# ESP32-P4-LP register map
Vendor: ESPRESSIF SYSTEMS (SHANGHAI) CO., LTD.; Series: ESP32 P-Series; File version: 3
CPU: RV32IMAC r0p0, little endian, no MPU, no FPU, 0 interrupt priority bits
Address unit: 32 bits
Registers are 32-bit, read-write, reset 0x0 unless marked. A register's access mark holds for its fields unless they carry their own. Offsets are from the block's base; [hi:lo] are bit positions; {n}, {i} and the like mark numbered series.

## LP_GPIO — Low-power General Purpose Input/Output
Base 0x5012A000
0x00 CLK_EN reset 0x1 — Reserved
  [0] REG_CLK_EN
0x04 VER_DATE reset 0x230323 — Reserved
  [27:0] REG_VER_DATE
0x08 OUT — Reserved
  [15:0] REG_GPIO_OUT_DATA
0x0C OUT_W1TS wo — Reserved
  [15:0] REG_GPIO_OUT_DATA_W1TS
0x10 OUT_W1TC wo — Reserved
  [15:0] REG_GPIO_OUT_DATA_W1TC
0x14 ENABLE — Reserved
  [15:0] REG_GPIO_ENABLE_DATA
0x18 ENABLE_W1TS wo — Reserved
  [15:0] REG_GPIO_ENABLE_DATA_W1TS
0x1C ENABLE_W1TC wo — Reserved
  [15:0] REG_GPIO_ENABLE_DATA_W1TC
0x20 STATUS — Reserved
  [15:0] REG_GPIO_STATUS_DATA
0x24 STATUS_W1TS wo — Reserved
  [15:0] REG_GPIO_STATUS_DATA_W1TS
0x28 STATUS_W1TC wo — Reserved
  [15:0] REG_GPIO_STATUS_DATA_W1TC
0x2C STATUS_NEXT ro — Reserved
  [15:0] REG_GPIO_STATUS_INTERRUPT_NEXT
0x30 IN ro — Reserved
  [15:0] REG_GPIO_IN_DATA_NEXT
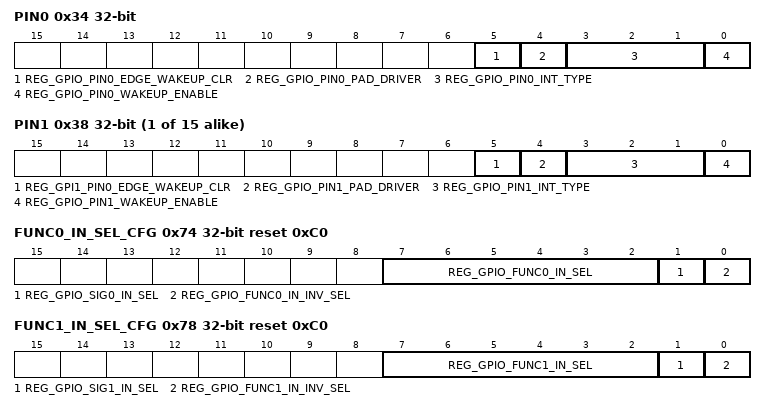
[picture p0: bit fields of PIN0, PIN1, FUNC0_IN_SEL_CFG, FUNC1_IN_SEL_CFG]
0x34 PIN0 access per field — Reserved
  [5] REG_GPIO_PIN0_EDGE_WAKEUP_CLR wo — need des
  [4] REG_GPIO_PIN0_PAD_DRIVER rw — Reserved
  [3:1] REG_GPIO_PIN0_INT_TYPE rw — Reserved
  [0] REG_GPIO_PIN0_WAKEUP_ENABLE rw — Reserved
{0x34+4i} PIN{i} access per field (i=1..15) — Reserved
  [5] REG_GPI{i}_PIN0_EDGE_WAKEUP_CLR wo — need des
  [4] REG_GPIO_PIN{i}_PAD_DRIVER rw — Reserved
  [3:1] REG_GPIO_PIN{i}_INT_TYPE rw — Reserved
  [0] REG_GPIO_PIN{i}_WAKEUP_ENABLE rw — Reserved
0x74 FUNC0_IN_SEL_CFG reset 0xC0 — Reserved
  [7:2] REG_GPIO_FUNC0_IN_SEL — reg_gpio_func0_in_sel[5:4]==2'b11->constant 1,reg_gpio_func0_in_sel[5:4]==2'b10->constant 0
  [1] REG_GPIO_SIG0_IN_SEL — Reserved
  [0] REG_GPIO_FUNC0_IN_INV_SEL — Reserved
0x78 FUNC1_IN_SEL_CFG reset 0xC0 — Reserved
  [7:2] REG_GPIO_FUNC1_IN_SEL — Reserved
  [1] REG_GPIO_SIG1_IN_SEL — Reserved
  [0] REG_GPIO_FUNC1_IN_INV_SEL — Reserved
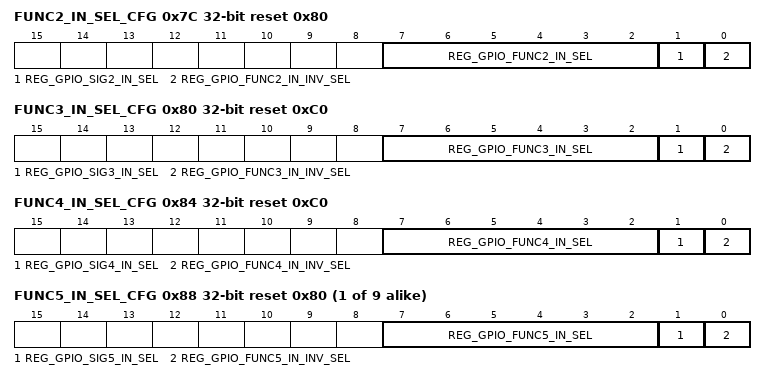
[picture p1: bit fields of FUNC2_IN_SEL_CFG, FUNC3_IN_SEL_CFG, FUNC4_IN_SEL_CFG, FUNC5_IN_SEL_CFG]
0x7C FUNC2_IN_SEL_CFG reset 0x80 — Reserved
  [7:2] REG_GPIO_FUNC2_IN_SEL — Reserved
  [1] REG_GPIO_SIG2_IN_SEL — Reserved
  [0] REG_GPIO_FUNC2_IN_INV_SEL — Reserved
0x80 FUNC3_IN_SEL_CFG reset 0xC0 — Reserved
  [7:2] REG_GPIO_FUNC3_IN_SEL — Reserved
  [1] REG_GPIO_SIG3_IN_SEL — Reserved
  [0] REG_GPIO_FUNC3_IN_INV_SEL — Reserved
0x84 FUNC4_IN_SEL_CFG reset 0xC0 — Reserved
  [7:2] REG_GPIO_FUNC4_IN_SEL — Reserved
  [1] REG_GPIO_SIG4_IN_SEL — Reserved
  [0] REG_GPIO_FUNC4_IN_INV_SEL — Reserved
{0x74+4i} FUNC{i}_IN_SEL_CFG reset 0x80 (i=5..13) — Reserved
  [7:2] REG_GPIO_FUNC{i}_IN_SEL — Reserved
  [1] REG_GPIO_SIG{i}_IN_SEL — Reserved
  [0] REG_GPIO_FUNC{i}_IN_INV_SEL — Reserved
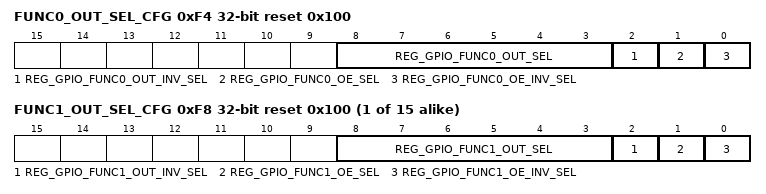
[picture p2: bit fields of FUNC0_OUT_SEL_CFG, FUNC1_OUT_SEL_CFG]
0xF4 FUNC0_OUT_SEL_CFG reset 0x100 — Reserved
  [8:3] REG_GPIO_FUNC0_OUT_SEL — reg_gpio_func0_out_sel[5:1]==16 -> output gpio register value to pad
  [2] REG_GPIO_FUNC0_OUT_INV_SEL — Reserved
  [1] REG_GPIO_FUNC0_OE_SEL — Reserved
  [0] REG_GPIO_FUNC0_OE_INV_SEL — Reserved
{0xF4+4i} FUNC{i}_OUT_SEL_CFG reset 0x100 (i=1..15) — Reserved
  [8:3] REG_GPIO_FUNC{i}_OUT_SEL — Reserved
  [2] REG_GPIO_FUNC{i}_OUT_INV_SEL — Reserved
  [1] REG_GPIO_FUNC{i}_OE_SEL — Reserved
  [0] REG_GPIO_FUNC{i}_OE_INV_SEL — Reserved

## LP_HUK — LP_HUK Peripheral
Base 0x50114000
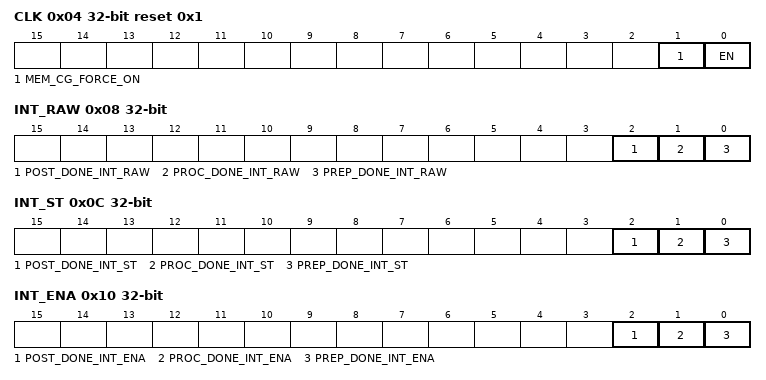
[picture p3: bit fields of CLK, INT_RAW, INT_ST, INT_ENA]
0x04 CLK reset 0x1 — HUK Generator clock gate control register
  [1] MEM_CG_FORCE_ON — Write 1 to force on memory clock gate.
  [0] EN — Write 1 to force on register clock gate.
0x08 INT_RAW ro — HUK Generator interrupt raw register, valid in level.
  [2] POST_DONE_INT_RAW — The raw interrupt status bit for the huk_post_done_int interrupt
  [1] PROC_DONE_INT_RAW — The raw interrupt status bit for the huk_proc_done_int interrupt
  [0] PREP_DONE_INT_RAW — The raw interrupt status bit for the huk_prep_done_int interrupt
0x0C INT_ST ro — HUK Generator interrupt status register.
  [2] POST_DONE_INT_ST — The masked interrupt status bit for the huk_post_done_int interrupt
  [1] PROC_DONE_INT_ST — The masked interrupt status bit for the huk_proc_done_int interrupt
  [0] PREP_DONE_INT_ST — The masked interrupt status bit for the huk_prep_done_int interrupt
0x10 INT_ENA — HUK Generator interrupt enable register.
  [2] POST_DONE_INT_ENA — The interrupt enable bit for the huk_post_done_int interrupt
  [1] PROC_DONE_INT_ENA — The interrupt enable bit for the huk_proc_done_int interrupt
  [0] PREP_DONE_INT_ENA — The interrupt enable bit for the huk_prep_done_int interrupt
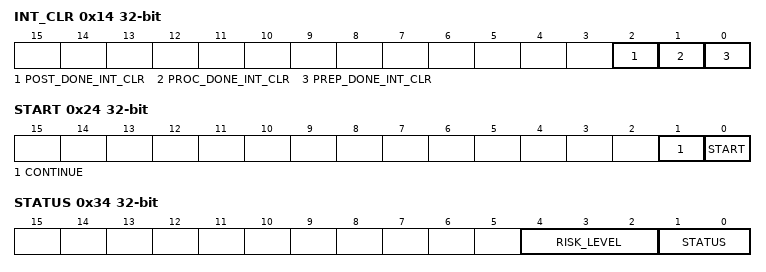
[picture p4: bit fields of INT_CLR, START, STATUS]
0x14 INT_CLR wo — HUK Generator interrupt clear register.
  [2] POST_DONE_INT_CLR — Set this bit to clear the huk_post_done_int interrupt
  [1] PROC_DONE_INT_CLR — Set this bit to clear the huk_proc_done_int interrupt
  [0] PREP_DONE_INT_CLR — Set this bit to clear the huk_prep_done_int interrupt
0x20 CONF — HUK Generator configuration register
  [0] MODE — Set this field to choose the huk process. 1: process huk generate mode. 0: process huk recovery mode.
0x24 START wo — HUK Generator control register
  [1] CONTINUE — Write 1 to start HUK Generator at IDLE state.
  [0] START — Write 1 to continue HUK Generator operation at LOAD/GAIN state.
0x28 STATE ro — HUK Generator state register
  [1:0] STATE — The state of HUK Generator. 0: IDLE. 1: LOAD. 2: GAIN. 3: BUSY.
0x34 STATUS ro — HUK Generator HUK status register
  [4:2] RISK_LEVEL — The risk level of HUK. 0-6: the higher the risk level is, the more error bits there are in the PUF SRAM. 7: Error Level, HUK is invalid.
  [1:0] STATUS — The HUK generation status. 0: HUK is not generated. 1: HUK is generated and valid. 2: HUK is generated but invalid. 3: reserved.
0xFC DATE reset 0x2305040 — Version control register
  [27:0] DATE — HUK Generator version control register.
{0x100+i} INFO_MEM[{i}] (i=0..383) 8-bit access not given — The memory that stores HUK info.
